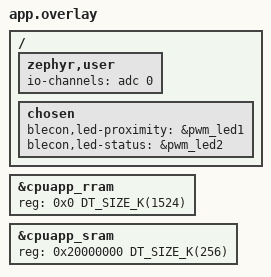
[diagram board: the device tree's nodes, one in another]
/*
 * Copyright (c) 2025 Blecon Ltd
 * SPDX-License-Identifier: Apache-2.0
 */

/ {
	zephyr,user {
    	io-channels = <&adc 0>;
   	};

	chosen {
		blecon,led-proximity = &pwm_led1;
		blecon,led-status = &pwm_led2;
	};
};

// We don't use cpuflpr, so allocate all RRAM abd SRAM to cpuapp
&cpuapp_rram {
	reg = <0x0 DT_SIZE_K(1524)>;
};

&cpuapp_sram {
    reg = <0x20000000 DT_SIZE_K(256)>;
};
